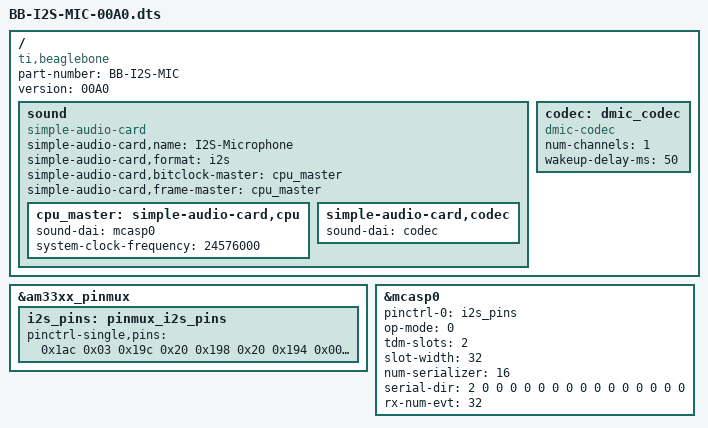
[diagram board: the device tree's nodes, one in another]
/*
 * Device Tree Overlay for INMP441/SPH0645 I2S MEMS Microphone
 * BeagleBone Black - McASP0 Configuration with 24.576 MHz CLKOUT2 Clock
 *
 * Hardware Required:
 *   - INMP441 or SPH0645 I2S MEMS Microphone
 *   - Jumper wire: P9_25 → P9_28 (routes 24.576 MHz clock to McASP)
 *
 * Pins used:
 *   P9_25 - CLKOUT2       (24.576 MHz clock OUTPUT - onboard oscillator)
 *   P9_28 - McASP0_AHCLKR (24.576 MHz clock INPUT to McASP)
 *   P9_29 - McASP0_FSX    (I2S Frame Sync / Word Select OUTPUT to mic)
 *   P9_30 - McASP0_AXR0   (I2S Data INPUT from mic)
 *   P9_31 - McASP0_ACLKX  (I2S Bit Clock OUTPUT to mic)
 *
 * Clock Strategy:
 *   BeagleBone Black has a 24.576 MHz oscillator on-board (for HDMI audio).
 *   This frequency is PERFECT for audio: 24.576 MHz / 512 = 48 kHz (exact).
 *
 *   Clock flow:
 *   1. CLKOUT2 (P9_25) outputs 24.576 MHz from onboard oscillator
 *   2. Jumper wire connects P9_25 → P9_28
 *   3. AHCLKR (P9_28) receives 24.576 MHz into McASP
 *   4. McASP divides this to generate BCLK (3.072 MHz for 48 kHz)
 *   5. McASP outputs BCLK on P9_31 to microphone
 *
 *   Result: 0% clock error (perfect 48 kHz sampling)
 *
 * Note: This disables HDMI audio to free up the CLKOUT2 signal.
 *
 * Sample rate: 48000 Hz (perfect accuracy)
 * Format: I2S
 * Channels: 1 (Mono - left channel)
 */

/dts-v1/;
/plugin/;

/ {
    compatible = "ti,beaglebone", "ti,beaglebone-black", "ti,beaglebone-green";

    /* Identification */
    part-number = "BB-I2S-MIC";
    version = "00A0";

    /* Pin mux configuration */
    fragment@0 {
        target = <&am33xx_pinmux>;
        __overlay__ {
            i2s_pins: pinmux_i2s_pins {
                pinctrl-single,pins = <
                    0x1ac 0x03  // P9_25: clkout2 (Mode 3, OUTPUT) - 24.576 MHz clock out
                    0x19c 0x20  // P9_28: mcasp0_ahclkr (Mode 0, INPUT | PULLDOWN) - Clock input to McASP
                    0x198 0x20  // P9_30: mcasp0_axr0 (Mode 0, INPUT | PULLDOWN) - Data from mic
                    0x194 0x00  // P9_29: mcasp0_fsx (Mode 0, OUTPUT | PULLDOWN) - Frame sync clock
                    0x190 0x00  // P9_31: mcasp0_aclkx (Mode 0, OUTPUT | PULLDOWN) - Bit clock
                >;
            };
        };
    };

    /* McASP0 configuration */
    fragment@1 {
        target = <&mcasp0>;
        __overlay__ {
            #sound-dai-cells = <0>;
            pinctrl-names = "default";
            pinctrl-0 = <&i2s_pins>;
            status = "okay";

            op-mode = <0>;  /* MCASP_IIS_MODE */
            tdm-slots = <2>;
            slot-width = <32>;  /* 32-bit slots for 24-bit data */
            num-serializer = <16>;

            /* Serial data pins:
             * 0 = inactive
             * 1 = TX (transmit)
             * 2 = RX (receive)
             * AXR0 = RX (receive data from microphone)
             */
            serial-dir = <
                2 0 0 0
                0 0 0 0
                0 0 0 0
                0 0 0 0
            >;

            rx-num-evt = <32>;
        };
    };

    /* Audio card configuration */
    fragment@2 {
        target-path = "/";
        __overlay__ {
            sound {
                compatible = "simple-audio-card";
                simple-audio-card,name = "I2S-Microphone";
                simple-audio-card,format = "i2s";
                simple-audio-card,bitclock-master = <&cpu_master>;
                simple-audio-card,frame-master = <&cpu_master>;

                cpu_master: simple-audio-card,cpu {
                    sound-dai = <&mcasp0>;
                    /* Use 24.576 MHz from CLKOUT2 via AHCLKR */
                    system-clock-frequency = <24576000>;
                };

                simple-audio-card,codec {
                    sound-dai = <&codec>;
                };
            };

            codec: dmic_codec {
                #sound-dai-cells = <0>;
                compatible = "dmic-codec";
                num-channels = <1>;
                wakeup-delay-ms = <50>;
                status = "okay";
            };
        };
    };
};
